VERSION ""

NS_ :

BS_:

BU_: RearECU FrontECU TSALgreen SDCreset HVDB HVAB

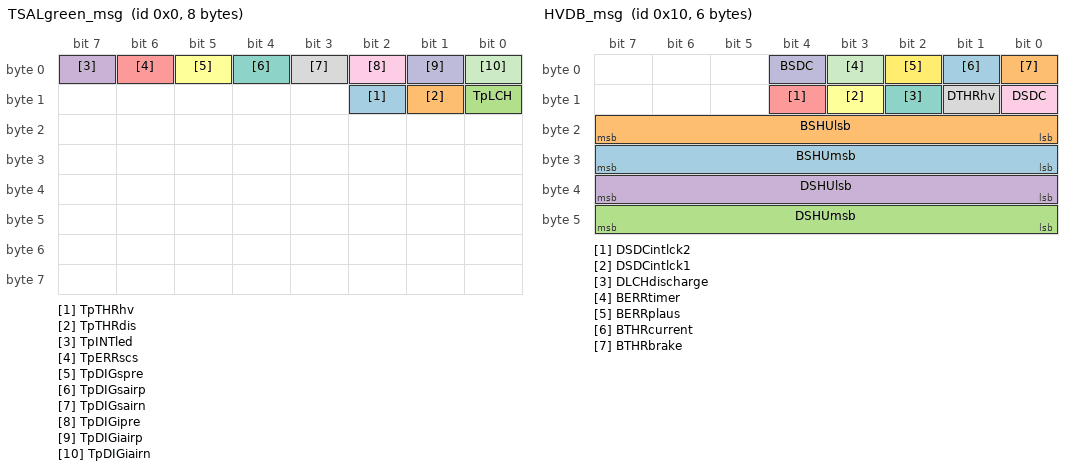
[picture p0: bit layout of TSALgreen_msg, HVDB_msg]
BO_ 0 TSALgreen_msg: 8 Vector__XXX
 SG_ TpTHRhv : 10|1@1+ (1,0) [0|1] "" Vector__XXX
 SG_ TpTHRdis : 9|1@1+ (1,0) [0|1] "" Vector__XXX
 SG_ TpLCH : 8|1@1+ (1,0) [0|1] "" Vector__XXX
 SG_ TpINTled : 7|1@1+ (1,0) [0|1] "" Vector__XXX
 SG_ TpERRscs : 6|1@1+ (1,0) [0|1] "" Vector__XXX
 SG_ TpDIGspre : 5|1@1+ (1,0) [0|1] "" Vector__XXX
 SG_ TpDIGsairp : 4|1@1+ (1,0) [0|1] "" Vector__XXX
 SG_ TpDIGsairn : 3|1@1+ (1,0) [0|1] "" Vector__XXX
 SG_ TpDIGipre : 2|1@1+ (1,0) [0|1] "" Vector__XXX
 SG_ TpDIGiairp : 1|1@1+ (1,0) [0|1] "" Vector__XXX
 SG_ TpDIGiairn : 0|1@1+ (1,0) [0|1] "" Vector__XXX

BO_ 16 HVDB_msg: 6 HVDB
 SG_ BSHUmsb : 24|8@1+ (1,0) [0|255] "mA" Vector__XXX
 SG_ BSHUlsb : 16|8@1+ (1,0) [0|255] "mA" Vector__XXX
 SG_ DSHUmsb : 40|8@1+ (1,0) [0|255] "mA" Vector__XXX
 SG_ DSHUlsb : 32|8@1+ (1,0) [0|255] "mA" Vector__XXX
 SG_ DSDCintlck2 : 12|1@1+ (1,0) [0|1] "" Vector__XXX
 SG_ DSDCintlck1 : 11|1@1+ (1,0) [0|1] "" Vector__XXX
 SG_ DLCHdischarge : 10|1@1+ (1,0) [0|1] "" Vector__XXX
 SG_ DTHRhv : 9|1@1+ (1,0) [0|1] "" Vector__XXX
 SG_ DSDC : 8|1@1+ (1,0) [0|1] "" Vector__XXX
 SG_ BSDC : 4|1@1+ (1,0) [0|1] "" Vector__XXX
 SG_ BERRtimer : 3|1@1+ (1,0) [0|1] "" Vector__XXX
 SG_ BERRplaus : 2|1@1+ (1,0) [0|1] "-" Vector__XXX
 SG_ BTHRcurrent : 1|1@1+ (1,0) [0|1] "-" Vector__XXX
 SG_ BTHRbrake : 0|1@1+ (1,0) [0|1] "-" Vector__XXX

BA_DEF_  "BusType" STRING ;
BA_DEF_DEF_  "BusType" "CAN";
